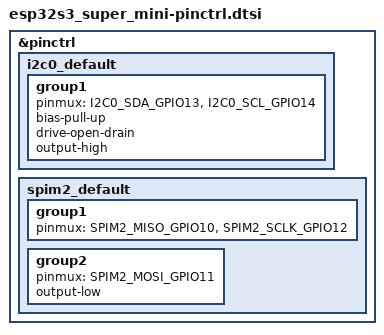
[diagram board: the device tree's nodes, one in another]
/*
 * Copyright (c) 2026 AkiraOS
 * SPDX-License-Identifier: Apache-2.0
 *
 * ESP32-S3 Super Mini Pinctrl Configuration
 */

#include <zephyr/dt-bindings/pinctrl/esp-pinctrl-common.h>
#include <dt-bindings/pinctrl/esp32s3-pinctrl.h>
#include <zephyr/dt-bindings/pinctrl/esp32s3-gpio-sigmap.h>

&pinctrl {
	/* I2C0: SDA=GPIO13, SCL=GPIO14 */
	i2c0_default: i2c0_default {
		group1 {
			pinmux = <I2C0_SDA_GPIO13>,
				 <I2C0_SCL_GPIO14>;
			bias-pull-up;
			drive-open-drain;
			output-high;
		};
	};

	/* SPI2: SCK=GPIO12, MOSI=GPIO11, MISO=GPIO10 */
	spim2_default: spim2_default {
		group1 {
			pinmux = <SPIM2_MISO_GPIO10>,
				 <SPIM2_SCLK_GPIO12>;
		};

		group2 {
			pinmux = <SPIM2_MOSI_GPIO11>;
			output-low;
		};
	};
};
